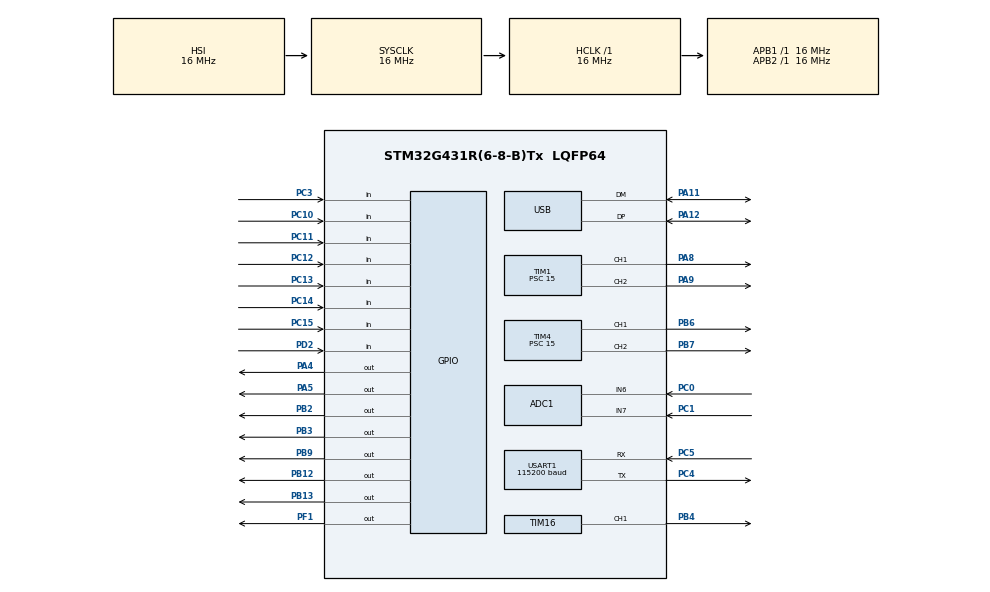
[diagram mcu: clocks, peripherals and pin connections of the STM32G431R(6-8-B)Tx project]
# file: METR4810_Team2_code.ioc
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ADC1.Channel-0\#ChannelRegularConversion=ADC_CHANNEL_6
ADC1.NbrOfConversionFlag=1
ADC1.OffsetNumber-0\#ChannelRegularConversion=ADC_OFFSET_NONE
ADC1.Rank-0\#ChannelRegularConversion=1
ADC1.SamplingTime-0\#ChannelRegularConversion=ADC_SAMPLETIME_2CYCLES_5
ADC1.SingleDiff-0\#ChannelRegularConversion=ADC_DIFFERENTIAL_ENDED
ADC1.master=1
Mcu.Family=STM32G4
Mcu.Name=STM32G431R(6-8-B)Tx
Mcu.Package=LQFP64
NVIC.PriorityGroup=NVIC_PRIORITYGROUP_4
NVIC.TIM1_UP_TIM16_IRQn=true\:1\:0\:false\:false\:true\:true\:true\:true
NVIC.USART1_IRQn=true\:2\:0\:false\:false\:true\:true\:true\:true
PA0.Signal=S_TIM2_CH1
PA1.Signal=S_TIM2_CH2
PA10.Signal=S_TIM1_CH3
PA11.Mode=Device
PA11.Signal=USB_DM
PA12.Mode=Device
PA12.Signal=USB_DP
PA13.Signal=SYS_JTMS-SWDIO
PA14.Signal=SYS_JTCK-SWCLK
PA2.Signal=S_TIM2_CH3
PA3.Signal=S_TIM2_CH4
PA4.Signal=GPIO_Output
PA5.Signal=GPIO_Output
PA6.Signal=S_TIM3_CH1
PA8.Signal=S_TIM1_CH1
PA9.Signal=S_TIM1_CH2
PB0.Signal=S_TIM3_CH3
PB1.Signal=S_TIM3_CH4
PB10.Signal=USART3_TX
PB11.Signal=USART3_RX
PB12.Signal=GPIO_Output
PB13.Signal=GPIO_Output
PB14.Signal=S_TIM15_CH1
PB15.Signal=S_TIM15_CH2
PB2.Signal=GPIO_Output
PB3.Signal=GPIO_Output
PB4.Signal=S_TIM16_CH1
PB5.Signal=S_TIM17_CH1
PB6.Signal=S_TIM4_CH1
PB7.Signal=S_TIM4_CH2
PB9.Signal=GPIO_Output
PC0.Mode=IN6-Differential
PC0.Signal=ADC1_IN6
PC1.Mode=IN6-Differential
PC1.Signal=ADC1_IN7
PC10.GPIO_PuPd=GPIO_PULLUP
PC10.Signal=GPIO_Input
PC11.GPIO_PuPd=GPIO_PULLUP
PC11.Signal=GPIO_Input
PC12.Signal=GPIO_Input
PC13.Signal=GPIO_Input
PC14-OSC32_IN.GPIO_PuPd=GPIO_PULLUP
PC14-OSC32_IN.Signal=GPIO_Input
PC15-OSC32_OUT.GPIO_PuPd=GPIO_PULLUP
PC15-OSC32_OUT.Signal=GPIO_Input
PC2.Signal=ADC1_IN8
PC3.GPIO_PuPd=GPIO_PULLDOWN
PC3.Signal=GPIO_Input
PC4.Mode=Asynchronous
PC4.Signal=USART1_TX
PC5.Mode=Asynchronous
PC5.Signal=USART1_RX
PC6.Signal=S_TIM8_CH1
PC7.Signal=S_TIM8_CH2
PC8.Signal=I2C3_SCL
PC9.Signal=I2C3_SDA
PD2.Signal=GPIO_Input
PF1-OSC_OUT.Signal=GPIO_Output
ProjectManager.HeapSize=0x200
ProjectManager.StackSize=0x400
ProjectManager.TargetToolchain=STM32CubeIDE
RCC.AHBFreq_Value=16000000
RCC.APB1Freq_Value=16000000
RCC.APB1TimFreq_Value=16000000
RCC.APB2Freq_Value=16000000
RCC.APB2TimFreq_Value=16000000
RCC.CortexFreq_Value=16000000
RCC.EXTERNAL_CLOCK_VALUE=12288000
RCC.HCLKFreq_Value=16000000
RCC.HSE_VALUE=8000000
RCC.HSI48_VALUE=48000000
RCC.HSI_VALUE=16000000
RCC.LSE_VALUE=32768
RCC.PLLN=12
RCC.PLLQ=RCC_PLLQ_DIV4
RCC.SYSCLKFreq_VALUE=16000000
RCC.USBFreq_Value=48000000
RCC.VCOOutputFreq_Value=192000000
SH.S_TIM15_CH1.0=TIM15_CH1
SH.S_TIM15_CH2.0=TIM15_CH2
SH.S_TIM16_CH1.0=TIM16_CH1,PWM Generation1 CH1
SH.S_TIM17_CH1.0=TIM17_CH1
SH.S_TIM1_CH1.0=TIM1_CH1,PWM Generation1 CH1
SH.S_TIM1_CH2.0=TIM1_CH2,PWM Generation2 CH2
SH.S_TIM1_CH3.0=TIM1_CH3
SH.S_TIM2_CH1.0=TIM2_CH1
SH.S_TIM2_CH2.0=TIM2_CH2
SH.S_TIM2_CH3.0=TIM2_CH3
SH.S_TIM2_CH4.0=TIM2_CH4
SH.S_TIM3_CH1.0=TIM3_CH1
SH.S_TIM3_CH3.0=TIM3_CH3
SH.S_TIM3_CH4.0=TIM3_CH4
SH.S_TIM4_CH1.0=TIM4_CH1,PWM Generation1 CH1
SH.S_TIM4_CH2.0=TIM4_CH2,PWM Generation2 CH2
SH.S_TIM8_CH1.0=TIM8_CH1
SH.S_TIM8_CH2.0=TIM8_CH2
TIM1.Channel-PWM\ Generation1\ CH1=TIM_CHANNEL_1
TIM1.Channel-PWM\ Generation2\ CH2=TIM_CHANNEL_2
TIM1.PeriodNoDither=999
TIM1.Prescaler=15
TIM1.PulseNoDither_1=500
TIM1.PulseNoDither_2=500
TIM16.Channel=TIM_CHANNEL_1
TIM16.PeriodNoDither=1999
TIM16.Prescaler=15
TIM16.PulseNoDither_1=1000
TIM4.Channel-PWM\ Generation1\ CH1=TIM_CHANNEL_1
TIM4.Channel-PWM\ Generation2\ CH2=TIM_CHANNEL_2
TIM4.PeriodNoDither=19999
TIM4.Prescaler=15
TIM4.PulseNoDither_1=1500
USART1.BaudRate=115200
USART1.VirtualMode-Asynchronous=VM_ASYNC
USART1.WordLength=WORDLENGTH_8B
USART1.Parity=PARITY_NONE
USART1.StopBits=STOPBITS_1
USART1.Mode=MODE_TX_RX
USART1.HwFlowCtl=HWCONTROL_NONE
VP_SYS_VS_DBSignals.Mode=DisableDeadBatterySignals
VP_TIM16_VS_ClockSourceINT.Mode=Enable_Timer
VP_TIM1_VS_ClockSourceINT.Mode=Internal
VP_TIM4_VS_ClockSourceINT.Mode=Internal
board=custom

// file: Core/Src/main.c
/* USER CODE BEGIN Header */
/**
  ******************************************************************************
  * @file           : main.c
  * @brief          : Main program body
  ******************************************************************************
  * @attention
  *
  * Copyright (c) 2026 STMicroelectronics.
  * All rights reserved.
  *
  * This software is licensed under terms that can be found in the LICENSE file
  * in the root directory of this software component.
  * If no LICENSE file comes with this software, it is provided AS-IS.
  *
  ******************************************************************************
  */
/* USER CODE END Header */
#include "main.h"

/* USER CODE BEGIN Includes */
#include "robot_control.h"
#include "serial.h"
#include "status_led.h"
/* USER CODE END Includes */

ADC_HandleTypeDef hadc1;

TIM_HandleTypeDef htim1;
TIM_HandleTypeDef htim4;
TIM_HandleTypeDef htim16;

UART_HandleTypeDef huart1;

PCD_HandleTypeDef hpcd_USB_FS;

void SystemClock_Config(void);
static void MX_GPIO_Init(void);
static void MX_ADC1_Init(void);
static void MX_USB_PCD_Init(void);
static void MX_TIM1_Init(void);
static void MX_TIM16_Init(void);
static void MX_TIM4_Init(void);
static void MX_USART1_UART_Init(void);

int main(void)
{

  /* MCU Configuration--------------------------------------------------------*/

  /* Reset of all peripherals, Initializes the Flash interface and the Systick. */

	HAL_Init();

  /* Configure the system clock */
  SystemClock_Config();

  /* Initialize all configured peripherals */
  MX_GPIO_Init();
  MX_ADC1_Init();
  MX_USB_PCD_Init();
  MX_TIM1_Init();
  MX_TIM16_Init();
  MX_TIM4_Init();
  MX_USART1_UART_Init();
  /* USER CODE BEGIN 2 */
  /* Bind drivers after CubeMX has configured clocks, GPIO and timers. */
  StatusLed_Init();
  Robot_Init(&htim1, &htim16, &htim4);
  Serial_Init(&huart1);
  /* USER CODE END 2 */

  /* Infinite loop */
  while (1)
  {

    /* USER CODE BEGIN 3 */
    /* Service motion/limits before parsing commands; keep every pass non-blocking. */
    Robot_Update();
    Serial_Update();
    StatusLed_Update();
  }
  /* USER CODE END 3 */
}

void SystemClock_Config(void)
{
  RCC_OscInitTypeDef RCC_OscInitStruct = {0};
  RCC_ClkInitTypeDef RCC_ClkInitStruct = {0};

  /** Configure the main internal regulator output voltage
  */
  HAL_PWREx_ControlVoltageScaling(PWR_REGULATOR_VOLTAGE_SCALE1);

  /** Initializes the RCC Oscillators according to the specified parameters
  * in the RCC_OscInitTypeDef structure.
  */
  RCC_OscInitStruct.OscillatorType = RCC_OSCILLATORTYPE_HSI;
  RCC_OscInitStruct.HSIState = RCC_HSI_ON;
  RCC_OscInitStruct.HSICalibrationValue = RCC_HSICALIBRATION_DEFAULT;
  RCC_OscInitStruct.PLL.PLLState = RCC_PLL_ON;
  RCC_OscInitStruct.PLL.PLLSource = RCC_PLLSOURCE_HSI;
  RCC_OscInitStruct.PLL.PLLM = RCC_PLLM_DIV1;
  RCC_OscInitStruct.PLL.PLLN = 12;
  RCC_OscInitStruct.PLL.PLLP = RCC_PLLP_DIV2;
  RCC_OscInitStruct.PLL.PLLQ = RCC_PLLQ_DIV4;
  RCC_OscInitStruct.PLL.PLLR = RCC_PLLR_DIV2;
  if (HAL_RCC_OscConfig(&RCC_OscInitStruct) != HAL_OK)
  {
    Error_Handler();
  }

  /** Initializes the CPU, AHB and APB buses clocks
  */
  RCC_ClkInitStruct.ClockType = RCC_CLOCKTYPE_HCLK|RCC_CLOCKTYPE_SYSCLK
                              |RCC_CLOCKTYPE_PCLK1|RCC_CLOCKTYPE_PCLK2;
  RCC_ClkInitStruct.SYSCLKSource = RCC_SYSCLKSOURCE_HSI;
  RCC_ClkInitStruct.AHBCLKDivider = RCC_SYSCLK_DIV1;
  RCC_ClkInitStruct.APB1CLKDivider = RCC_HCLK_DIV1;
  RCC_ClkInitStruct.APB2CLKDivider = RCC_HCLK_DIV1;

  if (HAL_RCC_ClockConfig(&RCC_ClkInitStruct, FLASH_LATENCY_0) != HAL_OK)
  {
    Error_Handler();
  }
}

static void MX_ADC1_Init(void)
{

  ADC_MultiModeTypeDef multimode = {0};
  ADC_ChannelConfTypeDef sConfig = {0};

  /** Common config
  */
  hadc1.Instance = ADC1;
  hadc1.Init.ClockPrescaler = ADC_CLOCK_SYNC_PCLK_DIV2;
  hadc1.Init.Resolution = ADC_RESOLUTION_12B;
  hadc1.Init.DataAlign = ADC_DATAALIGN_RIGHT;
  hadc1.Init.GainCompensation = 0;
  hadc1.Init.ScanConvMode = ADC_SCAN_DISABLE;
  hadc1.Init.EOCSelection = ADC_EOC_SINGLE_CONV;
  hadc1.Init.LowPowerAutoWait = DISABLE;
  hadc1.Init.ContinuousConvMode = DISABLE;
  hadc1.Init.NbrOfConversion = 1;
  hadc1.Init.DiscontinuousConvMode = DISABLE;
  hadc1.Init.ExternalTrigConv = ADC_SOFTWARE_START;
  hadc1.Init.ExternalTrigConvEdge = ADC_EXTERNALTRIGCONVEDGE_NONE;
  hadc1.Init.DMAContinuousRequests = DISABLE;
  hadc1.Init.Overrun = ADC_OVR_DATA_PRESERVED;
  hadc1.Init.OversamplingMode = DISABLE;
  if (HAL_ADC_Init(&hadc1) != HAL_OK)
  {
    Error_Handler();
  }

  /** Configure the ADC multi-mode
  */
  multimode.Mode = ADC_MODE_INDEPENDENT;
  if (HAL_ADCEx_MultiModeConfigChannel(&hadc1, &multimode) != HAL_OK)
  {
    Error_Handler();
  }

  /** Configure Regular Channel
  */
  sConfig.Channel = ADC_CHANNEL_6;
  sConfig.Rank = ADC_REGULAR_RANK_1;
  sConfig.SamplingTime = ADC_SAMPLETIME_2CYCLES_5;
  sConfig.SingleDiff = ADC_DIFFERENTIAL_ENDED;
  sConfig.OffsetNumber = ADC_OFFSET_NONE;
  sConfig.Offset = 0;
  if (HAL_ADC_ConfigChannel(&hadc1, &sConfig) != HAL_OK)
  {
    Error_Handler();
  }

}

static void MX_TIM1_Init(void)
{

  TIM_ClockConfigTypeDef sClockSourceConfig = {0};
  TIM_MasterConfigTypeDef sMasterConfig = {0};
  TIM_OC_InitTypeDef sConfigOC = {0};
  TIM_BreakDeadTimeConfigTypeDef sBreakDeadTimeConfig = {0};

  htim1.Instance = TIM1;
  htim1.Init.Prescaler = 15;
  htim1.Init.CounterMode = TIM_COUNTERMODE_UP;
  htim1.Init.Period = 999;
  htim1.Init.ClockDivision = TIM_CLOCKDIVISION_DIV1;
  htim1.Init.RepetitionCounter = 0;
  htim1.Init.AutoReloadPreload = TIM_AUTORELOAD_PRELOAD_DISABLE;
  if (HAL_TIM_Base_Init(&htim1) != HAL_OK)
  {
    Error_Handler();
  }
  sClockSourceConfig.ClockSource = TIM_CLOCKSOURCE_INTERNAL;
  if (HAL_TIM_ConfigClockSource(&htim1, &sClockSourceConfig) != HAL_OK)
  {
    Error_Handler();
  }
  if (HAL_TIM_PWM_Init(&htim1) != HAL_OK)
  {
    Error_Handler();
  }
  sMasterConfig.MasterOutputTrigger = TIM_TRGO_RESET;
  sMasterConfig.MasterOutputTrigger2 = TIM_TRGO2_RESET;
  sMasterConfig.MasterSlaveMode = TIM_MASTERSLAVEMODE_DISABLE;
  if (HAL_TIMEx_MasterConfigSynchronization(&htim1, &sMasterConfig) != HAL_OK)
  {
    Error_Handler();
  }
  sConfigOC.OCMode = TIM_OCMODE_PWM1;
  sConfigOC.Pulse = 500;
  sConfigOC.OCPolarity = TIM_OCPOLARITY_HIGH;
  sConfigOC.OCNPolarity = TIM_OCNPOLARITY_HIGH;
  sConfigOC.OCFastMode = TIM_OCFAST_DISABLE;
  sConfigOC.OCIdleState = TIM_OCIDLESTATE_RESET;
  sConfigOC.OCNIdleState = TIM_OCNIDLESTATE_RESET;
  if (HAL_TIM_PWM_ConfigChannel(&htim1, &sConfigOC, TIM_CHANNEL_1) != HAL_OK)
  {
    Error_Handler();
  }
  if (HAL_TIM_PWM_ConfigChannel(&htim1, &sConfigOC, TIM_CHANNEL_2) != HAL_OK)
  {
    Error_Handler();
  }
  sBreakDeadTimeConfig.OffStateRunMode = TIM_OSSR_DISABLE;
  sBreakDeadTimeConfig.OffStateIDLEMode = TIM_OSSI_DISABLE;
  sBreakDeadTimeConfig.LockLevel = TIM_LOCKLEVEL_OFF;
  sBreakDeadTimeConfig.DeadTime = 0;
  sBreakDeadTimeConfig.BreakState = TIM_BREAK_DISABLE;
  sBreakDeadTimeConfig.BreakPolarity = TIM_BREAKPOLARITY_HIGH;
  sBreakDeadTimeConfig.BreakFilter = 0;
  sBreakDeadTimeConfig.BreakAFMode = TIM_BREAK_AFMODE_INPUT;
  sBreakDeadTimeConfig.Break2State = TIM_BREAK2_DISABLE;
  sBreakDeadTimeConfig.Break2Polarity = TIM_BREAK2POLARITY_HIGH;
  sBreakDeadTimeConfig.Break2Filter = 0;
  sBreakDeadTimeConfig.Break2AFMode = TIM_BREAK_AFMODE_INPUT;
  sBreakDeadTimeConfig.AutomaticOutput = TIM_AUTOMATICOUTPUT_DISABLE;
  if (HAL_TIMEx_ConfigBreakDeadTime(&htim1, &sBreakDeadTimeConfig) != HAL_OK)
  {
    Error_Handler();
  }
  HAL_TIM_MspPostInit(&htim1);

}

static void MX_TIM4_Init(void)
{

  TIM_ClockConfigTypeDef sClockSourceConfig = {0};
  TIM_MasterConfigTypeDef sMasterConfig = {0};
  TIM_OC_InitTypeDef sConfigOC = {0};

  htim4.Instance = TIM4;
  htim4.Init.Prescaler = 15;
  htim4.Init.CounterMode = TIM_COUNTERMODE_UP;
  htim4.Init.Period = 19999;
  htim4.Init.ClockDivision = TIM_CLOCKDIVISION_DIV1;
  htim4.Init.AutoReloadPreload = TIM_AUTORELOAD_PRELOAD_DISABLE;
  if (HAL_TIM_Base_Init(&htim4) != HAL_OK)
  {
    Error_Handler();
  }
  sClockSourceConfig.ClockSource = TIM_CLOCKSOURCE_INTERNAL;
  if (HAL_TIM_ConfigClockSource(&htim4, &sClockSourceConfig) != HAL_OK)
  {
    Error_Handler();
  }
  if (HAL_TIM_PWM_Init(&htim4) != HAL_OK)
  {
    Error_Handler();
  }
  sMasterConfig.MasterOutputTrigger = TIM_TRGO_RESET;
  sMasterConfig.MasterSlaveMode = TIM_MASTERSLAVEMODE_DISABLE;
  if (HAL_TIMEx_MasterConfigSynchronization(&htim4, &sMasterConfig) != HAL_OK)
  {
    Error_Handler();
  }
  sConfigOC.OCMode = TIM_OCMODE_PWM1;
  sConfigOC.Pulse = 1500;
  sConfigOC.OCPolarity = TIM_OCPOLARITY_HIGH;
  sConfigOC.OCFastMode = TIM_OCFAST_DISABLE;
  if (HAL_TIM_PWM_ConfigChannel(&htim4, &sConfigOC, TIM_CHANNEL_1) != HAL_OK)
  {
    Error_Handler();
  }
  sConfigOC.Pulse = 0;
  if (HAL_TIM_PWM_ConfigChannel(&htim4, &sConfigOC, TIM_CHANNEL_2) != HAL_OK)
  {
    Error_Handler();
  }
  HAL_TIM_MspPostInit(&htim4);

}

static void MX_TIM16_Init(void)
{

  TIM_OC_InitTypeDef sConfigOC = {0};
  TIM_BreakDeadTimeConfigTypeDef sBreakDeadTimeConfig = {0};

  htim16.Instance = TIM16;
  htim16.Init.Prescaler = 15;
  htim16.Init.CounterMode = TIM_COUNTERMODE_UP;
  htim16.Init.Period = 1999;
  htim16.Init.ClockDivision = TIM_CLOCKDIVISION_DIV1;
  htim16.Init.RepetitionCounter = 0;
  htim16.Init.AutoReloadPreload = TIM_AUTORELOAD_PRELOAD_DISABLE;
  if (HAL_TIM_Base_Init(&htim16) != HAL_OK)
  {
    Error_Handler();
  }
  if (HAL_TIM_PWM_Init(&htim16) != HAL_OK)
  {
    Error_Handler();
  }
  sConfigOC.OCMode = TIM_OCMODE_PWM1;
  sConfigOC.Pulse = 1000;
  sConfigOC.OCPolarity = TIM_OCPOLARITY_HIGH;
  sConfigOC.OCNPolarity = TIM_OCNPOLARITY_HIGH;
  sConfigOC.OCFastMode = TIM_OCFAST_DISABLE;
  sConfigOC.OCIdleState = TIM_OCIDLESTATE_RESET;
  sConfigOC.OCNIdleState = TIM_OCNIDLESTATE_RESET;
  if (HAL_TIM_PWM_ConfigChannel(&htim16, &sConfigOC, TIM_CHANNEL_1) != HAL_OK)
  {
    Error_Handler();
  }
  sBreakDeadTimeConfig.OffStateRunMode = TIM_OSSR_DISABLE;
  sBreakDeadTimeConfig.OffStateIDLEMode = TIM_OSSI_DISABLE;
  sBreakDeadTimeConfig.LockLevel = TIM_LOCKLEVEL_OFF;
  sBreakDeadTimeConfig.DeadTime = 0;
  sBreakDeadTimeConfig.BreakState = TIM_BREAK_DISABLE;
  sBreakDeadTimeConfig.BreakPolarity = TIM_BREAKPOLARITY_HIGH;
  sBreakDeadTimeConfig.BreakFilter = 0;
  sBreakDeadTimeConfig.AutomaticOutput = TIM_AUTOMATICOUTPUT_DISABLE;
  if (HAL_TIMEx_ConfigBreakDeadTime(&htim16, &sBreakDeadTimeConfig) != HAL_OK)
  {
    Error_Handler();
  }
  HAL_TIM_MspPostInit(&htim16);

}

static void MX_USART1_UART_Init(void)
{

  huart1.Instance = USART1;
  huart1.Init.BaudRate = 115200;
  huart1.Init.WordLength = UART_WORDLENGTH_8B;
  huart1.Init.StopBits = UART_STOPBITS_1;
  huart1.Init.Parity = UART_PARITY_NONE;
  huart1.Init.Mode = UART_MODE_TX_RX;
  huart1.Init.HwFlowCtl = UART_HWCONTROL_NONE;
  huart1.Init.OverSampling = UART_OVERSAMPLING_16;
  huart1.Init.OneBitSampling = UART_ONE_BIT_SAMPLE_DISABLE;
  huart1.Init.ClockPrescaler = UART_PRESCALER_DIV1;
  huart1.AdvancedInit.AdvFeatureInit = UART_ADVFEATURE_NO_INIT;
  if (HAL_UART_Init(&huart1) != HAL_OK)
  {
    Error_Handler();
  }
  if (HAL_UARTEx_SetTxFifoThreshold(&huart1, UART_TXFIFO_THRESHOLD_1_8) != HAL_OK)
  {
    Error_Handler();
  }
  if (HAL_UARTEx_SetRxFifoThreshold(&huart1, UART_RXFIFO_THRESHOLD_1_8) != HAL_OK)
  {
    Error_Handler();
  }
  if (HAL_UARTEx_DisableFifoMode(&huart1) != HAL_OK)
  {
    Error_Handler();
  }

}

static void MX_USB_PCD_Init(void)
{

  hpcd_USB_FS.Instance = USB;
  hpcd_USB_FS.Init.dev_endpoints = 8;
  hpcd_USB_FS.Init.speed = PCD_SPEED_FULL;
  hpcd_USB_FS.Init.phy_itface = PCD_PHY_EMBEDDED;
  hpcd_USB_FS.Init.Sof_enable = DISABLE;
  hpcd_USB_FS.Init.low_power_enable = DISABLE;
  hpcd_USB_FS.Init.lpm_enable = DISABLE;
  hpcd_USB_FS.Init.battery_charging_enable = DISABLE;
  if (HAL_PCD_Init(&hpcd_USB_FS) != HAL_OK)
  {
    Error_Handler();
  }

}

static void MX_GPIO_Init(void)
{
  GPIO_InitTypeDef GPIO_InitStruct = {0};

  /* GPIO Ports Clock Enable */
  __HAL_RCC_GPIOC_CLK_ENABLE();
  __HAL_RCC_GPIOF_CLK_ENABLE();
  __HAL_RCC_GPIOA_CLK_ENABLE();
  __HAL_RCC_GPIOB_CLK_ENABLE();
  __HAL_RCC_GPIOD_CLK_ENABLE();

  /*Configure GPIO pin Output Level */
  HAL_GPIO_WritePin(GPIOF, GPIO_PIN_1, GPIO_PIN_RESET);

  /*Configure GPIO pin Output Level */
  HAL_GPIO_WritePin(GPIOA, GPIO_PIN_4|GPIO_PIN_5, GPIO_PIN_RESET);

  /*Configure GPIO pin Output Level */
  HAL_GPIO_WritePin(GPIOB, GPIO_PIN_2|GPIO_PIN_12|GPIO_PIN_13|GPIO_PIN_3
                          |GPIO_PIN_9, GPIO_PIN_RESET);

  /*Configure GPIO pins : PC13 PC12 */
  GPIO_InitStruct.Pin = GPIO_PIN_13|GPIO_PIN_12;
  GPIO_InitStruct.Mode = GPIO_MODE_INPUT;
  GPIO_InitStruct.Pull = GPIO_NOPULL;
  HAL_GPIO_Init(GPIOC, &GPIO_InitStruct);

  /*Configure GPIO pins : PC14 PC15 PC10 PC11 */
  GPIO_InitStruct.Pin = GPIO_PIN_14|GPIO_PIN_15|GPIO_PIN_10|GPIO_PIN_11;
  GPIO_InitStruct.Mode = GPIO_MODE_INPUT;
  GPIO_InitStruct.Pull = GPIO_PULLUP;
  HAL_GPIO_Init(GPIOC, &GPIO_InitStruct);

  /*Configure GPIO pin : PF1 */
  GPIO_InitStruct.Pin = GPIO_PIN_1;
  GPIO_InitStruct.Mode = GPIO_MODE_OUTPUT_PP;
  GPIO_InitStruct.Pull = GPIO_NOPULL;
  GPIO_InitStruct.Speed = GPIO_SPEED_FREQ_LOW;
  HAL_GPIO_Init(GPIOF, &GPIO_InitStruct);

  /*Configure GPIO pin : PC3 */
  GPIO_InitStruct.Pin = GPIO_PIN_3;
  GPIO_InitStruct.Mode = GPIO_MODE_INPUT;
  GPIO_InitStruct.Pull = GPIO_PULLDOWN;
  HAL_GPIO_Init(GPIOC, &GPIO_InitStruct);

  /*Configure GPIO pins : PA0 PA1 PA2 PA3 */
  GPIO_InitStruct.Pin = GPIO_PIN_0|GPIO_PIN_1|GPIO_PIN_2|GPIO_PIN_3;
  GPIO_InitStruct.Mode = GPIO_MODE_AF_PP;
  GPIO_InitStruct.Pull = GPIO_NOPULL;
  GPIO_InitStruct.Speed = GPIO_SPEED_FREQ_LOW;
  GPIO_InitStruct.Alternate = GPIO_AF1_TIM2;
  HAL_GPIO_Init(GPIOA, &GPIO_InitStruct);

  /*Configure GPIO pins : PA4 PA5 */
  GPIO_InitStruct.Pin = GPIO_PIN_4|GPIO_PIN_5;
  GPIO_InitStruct.Mode = GPIO_MODE_OUTPUT_PP;
  GPIO_InitStruct.Pull = GPIO_NOPULL;
  GPIO_InitStruct.Speed = GPIO_SPEED_FREQ_LOW;
  HAL_GPIO_Init(GPIOA, &GPIO_InitStruct);

  /*Configure GPIO pin : PA6 */
  GPIO_InitStruct.Pin = GPIO_PIN_6;
  GPIO_InitStruct.Mode = GPIO_MODE_AF_PP;
  GPIO_InitStruct.Pull = GPIO_NOPULL;
  GPIO_InitStruct.Speed = GPIO_SPEED_FREQ_LOW;
  GPIO_InitStruct.Alternate = GPIO_AF2_TIM3;
  HAL_GPIO_Init(GPIOA, &GPIO_InitStruct);

  /*Configure GPIO pins : PB0 PB1 */
  GPIO_InitStruct.Pin = GPIO_PIN_0|GPIO_PIN_1;
  GPIO_InitStruct.Mode = GPIO_MODE_AF_PP;
  GPIO_InitStruct.Pull = GPIO_NOPULL;
  GPIO_InitStruct.Speed = GPIO_SPEED_FREQ_LOW;
  GPIO_InitStruct.Alternate = GPIO_AF2_TIM3;
  HAL_GPIO_Init(GPIOB, &GPIO_InitStruct);

  /*Configure GPIO pins : PB2 PB12 PB13 PB3
                           PB9 */
  GPIO_InitStruct.Pin = GPIO_PIN_2|GPIO_PIN_12|GPIO_PIN_13|GPIO_PIN_3
                          |GPIO_PIN_9;
  GPIO_InitStruct.Mode = GPIO_MODE_OUTPUT_PP;
  GPIO_InitStruct.Pull = GPIO_NOPULL;
  GPIO_InitStruct.Speed = GPIO_SPEED_FREQ_LOW;
  HAL_GPIO_Init(GPIOB, &GPIO_InitStruct);

  /*Configure GPIO pins : PB10 PB11 */
  GPIO_InitStruct.Pin = GPIO_PIN_10|GPIO_PIN_11;
  GPIO_InitStruct.Mode = GPIO_MODE_AF_PP;
  GPIO_InitStruct.Pull = GPIO_NOPULL;
  GPIO_InitStruct.Speed = GPIO_SPEED_FREQ_LOW;
  GPIO_InitStruct.Alternate = GPIO_AF7_USART3;
  HAL_GPIO_Init(GPIOB, &GPIO_InitStruct);

  /*Configure GPIO pins : PB14 PB15 */
  GPIO_InitStruct.Pin = GPIO_PIN_14|GPIO_PIN_15;
  GPIO_InitStruct.Mode = GPIO_MODE_AF_PP;
  GPIO_InitStruct.Pull = GPIO_NOPULL;
  GPIO_InitStruct.Speed = GPIO_SPEED_FREQ_LOW;
  GPIO_InitStruct.Alternate = GPIO_AF1_TIM15;
  HAL_GPIO_Init(GPIOB, &GPIO_InitStruct);

  /*Configure GPIO pins : PC6 PC7 */
  GPIO_InitStruct.Pin = GPIO_PIN_6|GPIO_PIN_7;
  GPIO_InitStruct.Mode = GPIO_MODE_AF_PP;
  GPIO_InitStruct.Pull = GPIO_NOPULL;
  GPIO_InitStruct.Speed = GPIO_SPEED_FREQ_LOW;
  GPIO_InitStruct.Alternate = GPIO_AF4_TIM8;
  HAL_GPIO_Init(GPIOC, &GPIO_InitStruct);

  /*Configure GPIO pins : PC8 PC9 */
  GPIO_InitStruct.Pin = GPIO_PIN_8|GPIO_PIN_9;
  GPIO_InitStruct.Mode = GPIO_MODE_AF_OD;
  GPIO_InitStruct.Pull = GPIO_NOPULL;
  GPIO_InitStruct.Speed = GPIO_SPEED_FREQ_LOW;
  GPIO_InitStruct.Alternate = GPIO_AF8_I2C3;
  HAL_GPIO_Init(GPIOC, &GPIO_InitStruct);

  /*Configure GPIO pin : PD2 */
  GPIO_InitStruct.Pin = GPIO_PIN_2;
  GPIO_InitStruct.Mode = GPIO_MODE_INPUT;
  GPIO_InitStruct.Pull = GPIO_NOPULL;
  HAL_GPIO_Init(GPIOD, &GPIO_InitStruct);

  /*Configure GPIO pin : PB5 */
  GPIO_InitStruct.Pin = GPIO_PIN_5;
  GPIO_InitStruct.Mode = GPIO_MODE_AF_PP;
  GPIO_InitStruct.Pull = GPIO_NOPULL;
  GPIO_InitStruct.Speed = GPIO_SPEED_FREQ_LOW;
  GPIO_InitStruct.Alternate = GPIO_AF10_TIM17;
  HAL_GPIO_Init(GPIOB, &GPIO_InitStruct);

  /* USER CODE BEGIN MX_GPIO_Init_2 */
  /* ES/start button: PC3 is driven to 3.3 V when pressed. */
  GPIO_InitStruct.Pin = GPIO_PIN_3;
  GPIO_InitStruct.Mode = GPIO_MODE_INPUT;
  GPIO_InitStruct.Pull = GPIO_PULLDOWN;
  HAL_GPIO_Init(GPIOC, &GPIO_InitStruct);

  /* USER CODE END MX_GPIO_Init_2 */
}

void Error_Handler(void)
{
  __disable_irq();
  while (1)
  {
  }
}
